AUTOSAR XML (schema 4-0-3)
package /AUTOSAR_Det
  swc implementation Implementation: programming-language=C, sw-version=6.5.7, vendor-id=1, behavior=InternalBehavior
    code-descriptors:
      code Code: artifact-descriptors=autosar-engineering-object={short-label=EngObject, category=SWSRC}
    resource consumption Resources
      memory section CODE: sw-addrmethod=CODE
package /AUTOSAR_Det/SwComponentTypes
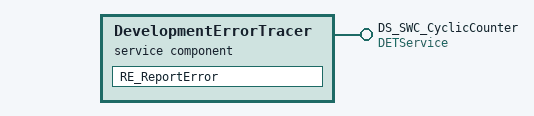
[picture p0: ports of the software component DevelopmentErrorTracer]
  service sw component type DevelopmentErrorTracer
    provide port DS_SWC_CyclicCounter: server-com-spec{operation=ReportError, queue-length=1}, provided-interface=DETService
    behavior InternalBehavior: handle-termination-and-restart=NO-SUPPORT, port-api-option{enable-take-address=false, indirect-api=false, port-defined-argument-value{value=256, value-type=uint16}, port=DS_SWC_CyclicCounter}
      operation invoked event EV_ReportError_SWC_CyclicCounter: start-on-event=RE_ReportError, operation=DS_SWC_CyclicCounter.ReportError
      runnable RE_ReportError: can-be-invoked-concurrently=true, symbol=Det_Rte_ReportError
